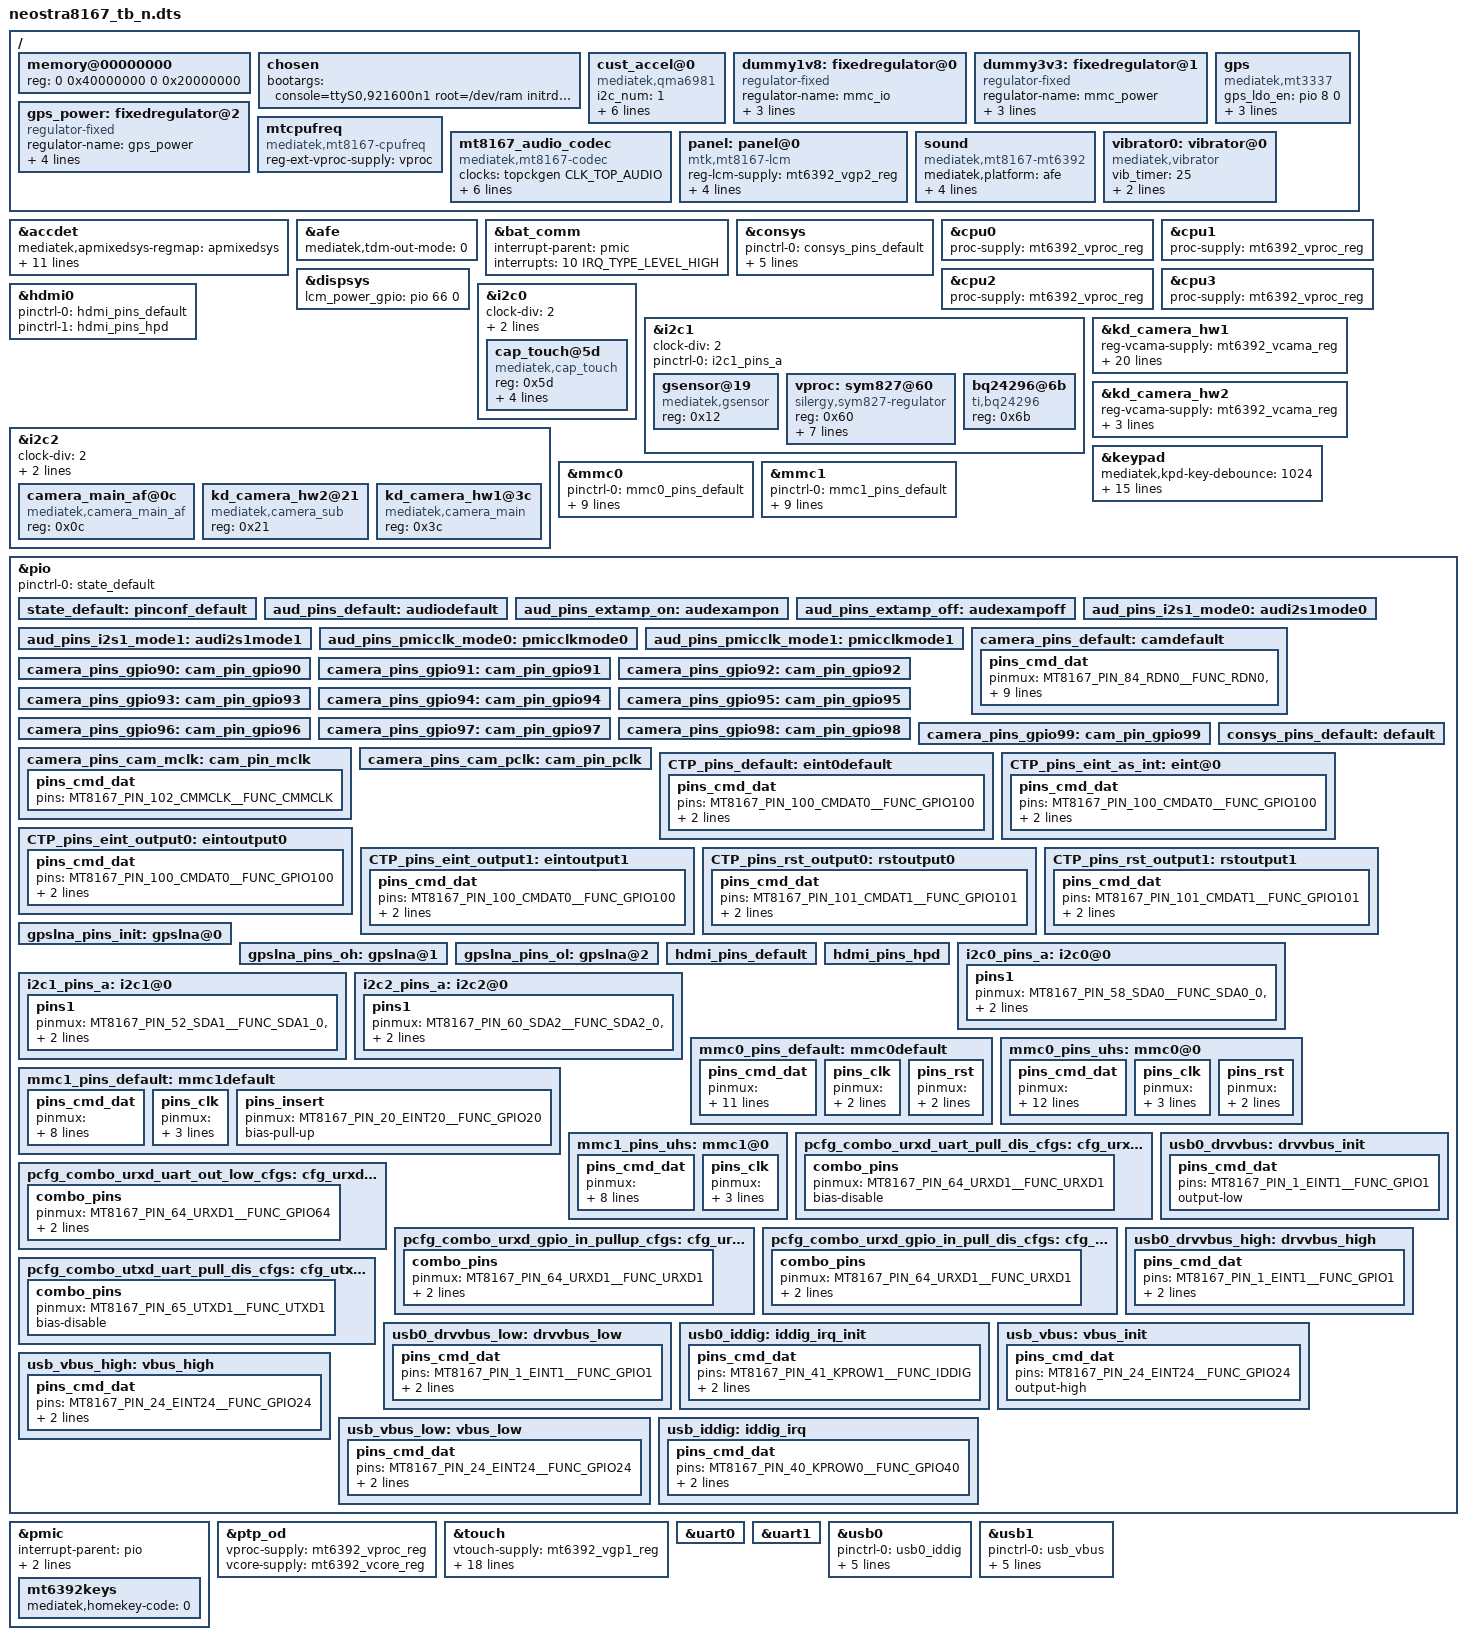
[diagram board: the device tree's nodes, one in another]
/*
 * Copyright (c) 2014-2015 MediaTek Inc.
 *
 * This program is free software; you can redistribute it and/or modify
 * it under the terms of the GNU General Public License version 2 as
 * published by the Free Software Foundation.
 *
 * This program is distributed in the hope that it will be useful,
 * MERCHANTABILITY or FITNESS FOR A PARTICULAR PURPOSE.  See the
 * GNU General Public License for more details.
 */

/dts-v1/;

#include "mt8167.dtsi"
#include "mt6392.dtsi"
#include "neostra8167_tb_n_bat_setting.dtsi"

/ {
	memory@00000000 {
		device_type = "memory";
		reg = <0 0x40000000 0 0x20000000>;
	};

	/* chosen */
	chosen {
		bootargs = "console=ttyS0,921600n1 root=/dev/ram initrd=0x44000200,0x200000";
	};

/* sensor standardization */
	cust_accel@0 {
		compatible = "mediatek,qma6981";
		i2c_num	= <1>;
		i2c_addr = <0x12 0 0 0>;
		direction = <7>;
		power_id = <0xffff>;
		power_vol = <0>;
		firlen = <16>;
		is_batch_supported = <0>;
	};
/* sensor gpio standization */

	dummy1v8: fixedregulator@0 {
		compatible = "regulator-fixed";
		regulator-name = "mmc_io";
		regulator-min-microvolt = <1800000>;
		regulator-max-microvolt = <1800000>;
		regulator-always-on;
	};

	dummy3v3: fixedregulator@1 {
		compatible = "regulator-fixed";
		regulator-name = "mmc_power";
		regulator-min-microvolt = <3300000>;
		regulator-max-microvolt = <3300000>;
		regulator-always-on;
	};
/*Begin Neostra huangxiaohui add:MT3377 GPS gpio*/
/* MT 3337 GPS gpio */
	gps: gps {
		compatible = "mediatek,mt3337";
        gps_ldo_en = <&pio 8 0>;
		gps_rst_en = <&pio 9 0>;
		gps_stb_en = <&pio 15 0>;
		power-supply = <&gps_power>;
		status = "okay";
	};

	gps_power: fixedregulator@2 {
		compatible = "regulator-fixed";
		regulator-name = "gps_power";
		regulator-min-microvolt = <3300000>;
		regulator-max-microvolt = <3300000>;
		gpio = <&pio 8 0>;
		enable-active-high;
	};
/*End Neostra huangxiaohui add:MT3377 GPS gpio*/
	mtcpufreq {
		compatible = "mediatek,mt8167-cpufreq";
		reg-ext-vproc-supply = <&vproc>;
	};

	mt8167_audio_codec: mt8167_audio_codec {
		compatible = "mediatek,mt8167-codec";
		clocks = <&topckgen CLK_TOP_AUDIO>;
		clock-names = "bus";
		mediatek,afe-regmap = <&afe>;
		mediatek,apmixedsys-regmap = <&apmixedsys>;
		mediatek,pwrap-regmap = <&pwrap>;
		mediatek,speaker-mode = <0>; /* 0(CLASSD) 1(CLASSAB) */
		mediatek,dmic-wire-mode = <1>; /* 0(ONE_WIRE) 1(TWO_WIRE) */
		mediatek,headphone-cap-sel = <1>; /* 0(10UF) 1(22UF) 2(33UF) 3(47UF) */
	};

	panel: panel@0 {
		compatible = "mtk,mt8167-lcm";
		reg-lcm-supply = <&mt6392_vgp2_reg>;
		lcm_reset_gpio = <&pio 25 0>;
		lcm_bias_en = <&pio 5 0>;
		lcm_stand_by = <&pio 6 0>;
		lcm_backlight_en = <&pio 54 0>;
		status = "okay";
	};


	sound: sound {
		compatible = "mediatek,mt8167-mt6392";
		mediatek,platform = <&afe>;
		mediatek,hp-spk-amp-warmup-time-us = <40000>;
		pinctrl-names = "default", "extamp_on", "extamp_off";
		pinctrl-0 = <&aud_pins_default>;
		pinctrl-1 = <&aud_pins_extamp_on>;
		pinctrl-2 = <&aud_pins_extamp_off>;
		status = "okay";
	};

	vibrator0:vibrator@0 {
		compatible = "mediatek,vibrator";
		vib_timer = <25>;
		vib_limit = <9>;
		vib_vol= <5>;
	};
};

&accdet {
	mediatek,apmixedsys-regmap = <&apmixedsys>;
	interrupts-extended = <&sysirq GIC_SPI 152 IRQ_TYPE_LEVEL_LOW>,
				<&pio 19 IRQ_TYPE_LEVEL_LOW>;
	interrupts = <19 IRQ_TYPE_LEVEL_LOW>;
	eint-debounce = <256000>;
	accdet-gpio = <&pio 19 0>;
	accdet-mic-vol = <1>;
	headset-mode-setting = <0x500 0x500 1 0x1f0 0x800 0x800 0x20>;
	accdet-plugout-debounce = <20>;
	/*1:ACC mode, 2:low cost without in bias, 6:low cost with in bias*/
	accdet-mic-mode = <1>;
	status = "okay";
};

&afe {
	/* 0(HDMI) 1(I2S) 2(TDM) */
	mediatek,tdm-out-mode = <0>;
};

&bat_comm {
	interrupt-parent = <&pmic>;
	interrupts = <10 IRQ_TYPE_LEVEL_HIGH>;
};

&consys {
	pinctrl-names = "default", "gps_lna_state_init", "gps_lna_state_oh", "gps_lna_state_ol";
	pinctrl-0 = <&consys_pins_default>;
	pinctrl-1 = <&gpslna_pins_init>;
	pinctrl-2 = <&gpslna_pins_oh>;
	pinctrl-3 = <&gpslna_pins_ol>;
	vcn18-supply = <&mt6392_vcn18_reg>;
	vcn35-supply = <&mt6392_vcn35_reg>;
	status = "okay";
};

&cpu0 {
	proc-supply = <&mt6392_vproc_reg>;
};

&cpu1 {
	proc-supply = <&mt6392_vproc_reg>;
};

&cpu2 {
	proc-supply = <&mt6392_vproc_reg>;
};

&cpu3 {
	proc-supply = <&mt6392_vproc_reg>;
};

&dispsys {
	lcm_power_gpio = <&pio 66 0>;
};

&hdmi0 {
	pinctrl-names = "default", "hdmi_hpd";
	pinctrl-0 = <&hdmi_pins_default>;
	pinctrl-1 = <&hdmi_pins_hpd>;
	status = "okay";
};

&i2c0 {
	clock-div = <2>;
	clock-frequency = <400000>;
	pinctrl-names = "default";
	pinctrl-0 = <&i2c0_pins_a>;
	status = "okay";

	cap_touch@5d {
		compatible = "mediatek,cap_touch";
		reg = <0x5d>;
		interrupt-parent = <&pio>;
		interrupts = <100 IRQ_TYPE_EDGE_FALLING>;
		int-gpio = <&pio 100 0>;
		rst-gpio = <&pio 101 0>;
	};
};

&i2c1 {
	clock-div = <2>;
	pinctrl-names = "default";
	pinctrl-0 = <&i2c1_pins_a>;
	status = "okay";

	gsensor@19 {
		compatible = "mediatek,gsensor";
		reg = <0x12>;
	};

	vproc: sym827@60 {
		compatible = "silergy,sym827-regulator";
		reg = <0x60>;
		regulator-name = "vproc";
		regulator-min-microvolt = <600000>;
		regulator-max-microvolt = <1387500>;
		regulator-enable-ramp-delay = <400>;
		regulator-ramp-delay = <8333>;
		regulator-always-on;
		vsel-gpio = <&pio 34 0>;
	};

	bq24296@6b {
		compatible = "ti,bq24296";
		reg = <0x6b>;
	};
};

&i2c2 {
	clock-div = <2>;
	clock-frequency = <400000>;
	pinctrl-names = "default";
	pinctrl-0 = <&i2c2_pins_a>;
	status = "okay";

	camera_main_af@0c {
		compatible = "mediatek,camera_main_af";
		reg = <0x0c>;
	};

	kd_camera_hw2@21 {
		compatible = "mediatek,camera_sub";
		reg = <0x21>;
	};

	kd_camera_hw1@3c {
		compatible = "mediatek,camera_main";
		reg = <0x3c>;
	};
};

/* Main Cam */
&kd_camera_hw1 {
	reg-vcama-supply = <&mt6392_vcama_reg>;		/* AVDD */
	reg-vcamd-supply = <&mt6392_vcamd_reg>;		/* DVDD */
	reg-vcamio-supply = <&mt6392_vcamio_reg>;	/* DOVDD */
	reg-vcamaf-supply = <&mt6392_vcamaf_reg>;	/* AFVDD */

	pinctrl-names = "default",
		"cam_mclk", "cam_pclk",
		"cam_gpio90",  "cam_gpio91", "cam_gpio92", "cam_gpio93",  "cam_gpio94",
		"cam_gpio95",  "cam_gpio96", "cam_gpio97", "cam_gpio98",  "cam_gpio99";

	pinctrl-0 = <&camera_pins_default>;
	pinctrl-1 = <&camera_pins_cam_mclk>;
	pinctrl-2 = <&camera_pins_cam_pclk>;
	pinctrl-3 = <&camera_pins_gpio90>;
	pinctrl-4 = <&camera_pins_gpio91>;
	pinctrl-5 = <&camera_pins_gpio92>;
	pinctrl-6 = <&camera_pins_gpio93>;
	pinctrl-7 = <&camera_pins_gpio94>;
	pinctrl-8 = <&camera_pins_gpio95>;
	pinctrl-9 = <&camera_pins_gpio96>;
	pinctrl-10 = <&camera_pins_gpio97>;
	pinctrl-11 = <&camera_pins_gpio98>;
	pinctrl-12 = <&camera_pins_gpio99>;

	cam0_rst = <&pio 49 0>;
	cam0_pdn = <&pio 48 0>;
	cam1_rst = <&pio 50 0>;
	cam1_pdn = <&pio 51 0>;
	status = "okay";
};

/* Sub Cam */
/* Same power pins as Main, actually, it can be commented */
&kd_camera_hw2{
	reg-vcama-supply = <&mt6392_vcama_reg>;		/* AVDD */
	reg-vcamd-supply = <&mt6392_vcamd_reg>;		/* DVDD */
	reg-vcamio-supply = <&mt6392_vcamio_reg>;	/* DOVDD */
	reg-vcamaf-supply = <&mt6392_vcamaf_reg>;	/* AFVDD */
};

&keypad {
	mediatek,kpd-key-debounce = <1024>;
	mediatek,kpd-sw-pwrkey = <116>;
	mediatek,kpd-hw-pwrkey = <8>;
	mediatek,kpd-sw-rstkey  = <0>;
	mediatek,kpd-hw-rstkey = <17>;
	mediatek,kpd-use-extend-type = <0>;
	/*HW Keycode [0~71] -> Linux Keycode*/
	mediatek,kpd-hw-map-num = <72>;
	mediatek,kpd-hw-init-map = <114 115 0 0 0 0 0 0 0 0 0 0 0 0 0 0 0 0 0 0 0 0 0 0
			0 0 0 0 0 0 0 0 0 0 0 0 0 0 0 0 0 0 0 0 0 0 0 0
			0 0 0 0 0 0 0 0 0 0 0 0 0 0 0 0 0 0 0 0 0 0 0 0 >;
	mediatek,kpd-pwrkey-eint-gpio = <0>;
	mediatek,kpd-pwkey-gpio-din  = <0>;
	mediatek,kpd-hw-dl-key0 = <0>;
	mediatek,kpd-hw-dl-key1 = <17>;
	mediatek,kpd-hw-dl-key2 = <8>;
	mediatek,kpd-hw-recovery-key = <17>;
	mediatek,kpd-hw-factory-key  = <0>;
};

&mmc0 {
	pinctrl-names = "default", "state_uhs";
	pinctrl-0 = <&mmc0_pins_default>;
	pinctrl-1 = <&mmc0_pins_uhs>;
	status = "okay";
	bus-width = <8>;
	max-frequency = <200000000>;
	cap-mmc-highspeed;
	mmc-hs200-1_8v;
	cap-mmc-hw-reset;
	vmmc-supply = <&mt6392_vemc3v3_reg>;
	vqmmc-supply = <&mt6392_vio18_reg>;
	non-removable;
};

&mmc1 {
	pinctrl-names = "default", "state_uhs";
	pinctrl-0 = <&mmc1_pins_default>;
	pinctrl-1 = <&mmc1_pins_uhs>;
	status = "okay";
	bus-width = <4>;
	max-frequency = <200000000>;
	cap-sd-highspeed;
	sd-uhs-sdr50;
	sd-uhs-sdr104;
	cd-gpios = <&pio 20 0>;
	vmmc-supply = <&mt6392_vmch_reg>;
	vqmmc-supply = <&mt6392_vmc_reg>;
};


&pio {
	pinctrl-names = "default";
	pinctrl-0 = <&state_default>;

	state_default:pinconf_default {
	};

	aud_pins_default: audiodefault {
	};

	aud_pins_extamp_on: audexampon {
	};

	aud_pins_extamp_off: audexampoff {
	};

	aud_pins_i2s1_mode0: audi2s1mode0 {
	};

	aud_pins_i2s1_mode1: audi2s1mode1 {
	};

	aud_pins_pmicclk_mode0: pmicclkmode0 {
	};

	aud_pins_pmicclk_mode1: pmicclkmode1 {
	};

	/* CAMERA GPIO standardization */
	/* default mode */
	camera_pins_default: camdefault {

		pins_cmd_dat {
			pinmux = <MT8167_PIN_84_RDN0__FUNC_RDN0>,
				<MT8167_PIN_85_RDP0__FUNC_RDP0>,
				<MT8167_PIN_86_RDN1__FUNC_RDN1>,
				<MT8167_PIN_87_RDP1__FUNC_RDP1>,
				<MT8167_PIN_88_RCN__FUNC_RCN>,
				<MT8167_PIN_89_RCP__FUNC_RCP>,
				<MT8167_PIN_90_RDN2__FUNC_RDN2>,
				<MT8167_PIN_91_RDP2__FUNC_RDP2>,
				<MT8167_PIN_92_RDN3__FUNC_RDN3>,
				<MT8167_PIN_93_RDP3__FUNC_RDP3>;
		};
	};



	camera_pins_gpio90: cam_pin_gpio90 {
	};

	camera_pins_gpio91: cam_pin_gpio91 {
	};

	camera_pins_gpio92: cam_pin_gpio92 {
	};

	camera_pins_gpio93: cam_pin_gpio93 {
	};

	camera_pins_gpio94: cam_pin_gpio94 {
	};

	camera_pins_gpio95: cam_pin_gpio95 {
	};

	camera_pins_gpio96: cam_pin_gpio96 {
	};

	camera_pins_gpio97: cam_pin_gpio97 {
	};

	camera_pins_gpio98: cam_pin_gpio98 {
	};

	camera_pins_gpio99: cam_pin_gpio99 {
	};
	camera_pins_cam_mclk: cam_pin_mclk {
		pins_cmd_dat {
			pins = <MT8167_PIN_102_CMMCLK__FUNC_CMMCLK>;
		};
	};
	camera_pins_cam_pclk: cam_pin_pclk {
	};

	/* CONSYS GPIO Settings - Start */
	consys_pins_default: default {

	};
	/* CONSYS GPIO Settings - End */

	CTP_pins_default: eint0default {
		pins_cmd_dat {
			pins = <MT8167_PIN_100_CMDAT0__FUNC_GPIO100>;
			slew-rate = <0>;
			bias-disable;
		};
	};

	CTP_pins_eint_as_int: eint@0 {
		pins_cmd_dat {
			pins = <MT8167_PIN_100_CMDAT0__FUNC_GPIO100>;
			slew-rate = <0>;
			bias-disable;
		};
	};

	CTP_pins_eint_output0: eintoutput0 {
		pins_cmd_dat {
			pins = <MT8167_PIN_100_CMDAT0__FUNC_GPIO100>;
			slew-rate = <1>;
			output-low;
		};
	};

	CTP_pins_eint_output1: eintoutput1 {
		pins_cmd_dat {
			pins = <MT8167_PIN_100_CMDAT0__FUNC_GPIO100>;
			slew-rate = <1>;
			output-high;
		};
	};

	CTP_pins_rst_output0: rstoutput0 {
		pins_cmd_dat {
			pins = <MT8167_PIN_101_CMDAT1__FUNC_GPIO101>;
			slew-rate = <1>;
			output-low;
		};
	};

	CTP_pins_rst_output1: rstoutput1 {
		pins_cmd_dat {
			pins = <MT8167_PIN_101_CMDAT1__FUNC_GPIO101>;
			slew-rate = <1>;
			output-high;
		};
	};

	/* CONSYS GPIO Settings - Start */
	consys_pins_default:default{
	};
	
	gpslna_pins_init: gpslna@0 {
	};

	gpslna_pins_oh: gpslna@1 {
	};

	gpslna_pins_ol: gpslna@2 {
	};
	/* CONSYS GPIO Settings - End */

	hdmi_pins_default: hdmi_pins_default {
	};

	hdmi_pins_hpd: hdmi_pins_hpd {
	};

	i2c0_pins_a: i2c0@0 {
		pins1 {
			pinmux = <MT8167_PIN_58_SDA0__FUNC_SDA0_0>,
				 <MT8167_PIN_59_SCL0__FUNC_SCL0_0>;
			bias-disable;
		};
	};

	i2c1_pins_a: i2c1@0 {
		pins1 {
			pinmux = <MT8167_PIN_52_SDA1__FUNC_SDA1_0>,
				 <MT8167_PIN_53_SCL1__FUNC_SCL1_0>;
			bias-disable;
		};
	};

	i2c2_pins_a: i2c2@0 {
		pins1 {
			pinmux = <MT8167_PIN_60_SDA2__FUNC_SDA2_0>,
				 <MT8167_PIN_61_SCL2__FUNC_SCL2_0>;
			bias-disable;
		};
	};


	mmc0_pins_default: mmc0default {
		pins_cmd_dat {
			pinmux = <MT8167_PIN_120_MSDC0_DAT0__FUNC_MSDC0_DAT0>,
				<MT8167_PIN_119_MSDC0_DAT1__FUNC_MSDC0_DAT1>,
				<MT8167_PIN_118_MSDC0_DAT2__FUNC_MSDC0_DAT2>,
				<MT8167_PIN_117_MSDC0_DAT3__FUNC_MSDC0_DAT3>,
				<MT8167_PIN_113_MSDC0_DAT4__FUNC_MSDC0_DAT4>,
				<MT8167_PIN_112_MSDC0_DAT5__FUNC_MSDC0_DAT5>,
				<MT8167_PIN_111_MSDC0_DAT6__FUNC_MSDC0_DAT6>,
				<MT8167_PIN_110_MSDC0_DAT7__FUNC_MSDC0_DAT7>,
				<MT8167_PIN_115_MSDC0_CMD__FUNC_MSDC0_CMD>;
			input-enable;
			bias-pull-up;
		};

		pins_clk {
			pinmux = <MT8167_PIN_116_MSDC0_CLK__FUNC_MSDC0_CLK>;
			bias-pull-down;
		};

		pins_rst {
			pinmux = <MT8167_PIN_114_MSDC0_RSTB__FUNC_MSDC0_RSTB>;
			bias-pull-up;
		};
	};

	mmc0_pins_uhs: mmc0@0{
		pins_cmd_dat {
			pinmux = <MT8167_PIN_120_MSDC0_DAT0__FUNC_MSDC0_DAT0>,
				<MT8167_PIN_119_MSDC0_DAT1__FUNC_MSDC0_DAT1>,
				<MT8167_PIN_118_MSDC0_DAT2__FUNC_MSDC0_DAT2>,
				<MT8167_PIN_117_MSDC0_DAT3__FUNC_MSDC0_DAT3>,
				<MT8167_PIN_113_MSDC0_DAT4__FUNC_MSDC0_DAT4>,
				<MT8167_PIN_112_MSDC0_DAT5__FUNC_MSDC0_DAT5>,
				<MT8167_PIN_111_MSDC0_DAT6__FUNC_MSDC0_DAT6>,
				<MT8167_PIN_110_MSDC0_DAT7__FUNC_MSDC0_DAT7>,
				<MT8167_PIN_115_MSDC0_CMD__FUNC_MSDC0_CMD>;
			input-enable;
			drive-strength = <MTK_DRIVE_6mA>;
			bias-pull-up = <MTK_PUPD_SET_R1R0_01>;
		};

		pins_clk {
			pinmux = <MT8167_PIN_116_MSDC0_CLK__FUNC_MSDC0_CLK>;
			drive-strength = <MTK_DRIVE_8mA>;
			bias-pull-down = <MTK_PUPD_SET_R1R0_10>;
		};

		pins_rst {
			pinmux = <MT8167_PIN_114_MSDC0_RSTB__FUNC_MSDC0_RSTB>;
			bias-pull-up;
		};
	};

	mmc1_pins_default: mmc1default {
		pins_cmd_dat {
			pinmux = <MT8167_PIN_106_MSDC1_DAT0__FUNC_MSDC1_DAT0>,
				<MT8167_PIN_107_MSDC1_DAT1__FUNC_MSDC1_DAT1>,
				<MT8167_PIN_108_MSDC1_DAT2__FUNC_MSDC1_DAT2>,
				<MT8167_PIN_109_MSDC1_DAT3__FUNC_MSDC1_DAT3>,
				<MT8167_PIN_104_MSDC1_CMD__FUNC_MSDC1_CMD>;
			input-enable;
			drive-strength = <MTK_DRIVE_6mA>;
			bias-pull-up = <MTK_PUPD_SET_R1R0_01>;
		};

		pins_clk {
			pinmux = <MT8167_PIN_105_MSDC1_CLK__FUNC_MSDC1_CLK>;
			drive-strength = <MTK_DRIVE_6mA>;
			bias-pull-down = <MTK_PUPD_SET_R1R0_10>;
		};

		pins_insert {
			pinmux = <MT8167_PIN_20_EINT20__FUNC_GPIO20>;
			bias-pull-up;
		};
	};

	mmc1_pins_uhs: mmc1@0 {
		pins_cmd_dat {
			pinmux = <MT8167_PIN_106_MSDC1_DAT0__FUNC_MSDC1_DAT0>,
				<MT8167_PIN_107_MSDC1_DAT1__FUNC_MSDC1_DAT1>,
				<MT8167_PIN_108_MSDC1_DAT2__FUNC_MSDC1_DAT2>,
				<MT8167_PIN_109_MSDC1_DAT3__FUNC_MSDC1_DAT3>,
				<MT8167_PIN_104_MSDC1_CMD__FUNC_MSDC1_CMD>;
			input-enable;
			drive-strength = <MTK_DRIVE_6mA>;
			bias-pull-up = <MTK_PUPD_SET_R1R0_01>;
		};

		pins_clk {
			pinmux = <MT8167_PIN_105_MSDC1_CLK__FUNC_MSDC1_CLK>;
			drive-strength = <MTK_DRIVE_8mA>;
			bias-pull-down = <MTK_PUPD_SET_R1R0_10>;
		};
	};



    /* Connectivity GPIO start */


	pcfg_combo_urxd_uart_pull_dis_cfgs:cfg_urxd_pull_dis {
		combo_pins {
			pinmux = <MT8167_PIN_64_URXD1__FUNC_URXD1>;
			bias-disable;
		};
	};

	pcfg_combo_urxd_uart_out_low_cfgs:cfg_urxd_out_low {
		combo_pins {
			pinmux = <MT8167_PIN_64_URXD1__FUNC_GPIO64>;
			slew-rate = <1>;
			output-low;
		};
	};

	pcfg_combo_urxd_gpio_in_pullup_cfgs:cfg_urxd_in_pullup {
		combo_pins {
			pinmux = <MT8167_PIN_64_URXD1__FUNC_URXD1>;
			input-enable;
			bias-pull-up;
		};
	};

	pcfg_combo_urxd_gpio_in_pull_dis_cfgs:cfg_urxd_in_pull_dis {
		combo_pins {
			pinmux = <MT8167_PIN_64_URXD1__FUNC_URXD1>;
			input-enable;
			bias-disable;
		};
	};

	pcfg_combo_utxd_uart_pull_dis_cfgs:cfg_utxd_pull_dis {
		combo_pins {
			pinmux = <MT8167_PIN_65_UTXD1__FUNC_UTXD1>;
			bias-disable;
		};
	};
/* Connectivity GPIO end */

/* USB GPIO start */
	usb0_drvvbus: drvvbus_init {
		pins_cmd_dat {
			pins = <MT8167_PIN_1_EINT1__FUNC_GPIO1>;
			output-low;
		};
	};

	usb0_drvvbus_high: drvvbus_high {
		pins_cmd_dat {
			pins = <MT8167_PIN_1_EINT1__FUNC_GPIO1>;
			slew-rate = <1>;
			output-high;
		};
	};

	usb0_drvvbus_low: drvvbus_low {
		pins_cmd_dat {
			pins = <MT8167_PIN_1_EINT1__FUNC_GPIO1>;
			slew-rate = <1>;
			output-low;
		};
	};

	usb0_iddig: iddig_irq_init {
		pins_cmd_dat {
			pins = <MT8167_PIN_41_KPROW1__FUNC_IDDIG>;
			slew-rate = <0>;
			bias-pull-up = <00>;
		};
	};

	usb_vbus: vbus_init {
		pins_cmd_dat {
			pins = <MT8167_PIN_24_EINT24__FUNC_GPIO24>;
			output-high;
		};
	};

	usb_vbus_high: vbus_high {
		pins_cmd_dat {
			pins = <MT8167_PIN_24_EINT24__FUNC_GPIO24>;
			slew-rate = <1>;
			output-high;
		};
	};

	usb_vbus_low: vbus_low {
		pins_cmd_dat {
			pins = <MT8167_PIN_24_EINT24__FUNC_GPIO24>;
			slew-rate = <1>;
			output-low;
		};
	};

	usb_iddig: iddig_irq {
		pins_cmd_dat {
			pins = <MT8167_PIN_40_KPROW0__FUNC_GPIO40>;
			slew-rate = <0>;
			bias-pull-up = <00>;
		};
	};
/* USB GPIO end */
};

&pmic {
	interrupt-parent = <&pio>;
	interrupts = <28 IRQ_TYPE_LEVEL_HIGH>;
	interrupt-controller;
	#interrupt-cells = <2>;

	mt6392keys: mt6392keys {
		mediatek,homekey-code = <0>;
	};
};

&ptp_od {
	vproc-supply = <&mt6392_vproc_reg>;
	vcore-supply = <&mt6392_vcore_reg>;
};

&touch {
	vtouch-supply = <&mt6392_vgp1_reg>;
	tpd-resolution = <600 1024>;
	use-tpd-button = <0>;
	tpd-key-num = <3>;
	tpd-key-local= <139 172 158 0>;
	tpd-key-dim-local = <90 883 100 40 230 883 100 40 370 883 100 40 0 0 0 0>;
	tpd-max-touch-num = <5>;
	tpd-filter-enable = <1>;
	tpd-filter-pixel-density = <124>;
	tpd-filter-custom-prameters = <0 0 0 0 0 0 0 0 0 0 0 0>;
	tpd-filter-custom-speed = <0 0 0>;
	pinctrl-names = "default", "state_eint_as_int", "state_eint_output0", "state_eint_output1",
		"state_rst_output0", "state_rst_output1";
	pinctrl-0 = <&CTP_pins_default>;
	pinctrl-1 = <&CTP_pins_eint_as_int>;
	pinctrl-2 = <&CTP_pins_eint_output0>;
	pinctrl-3 = <&CTP_pins_eint_output1>;
	pinctrl-4 = <&CTP_pins_rst_output0>;
	pinctrl-5 = <&CTP_pins_rst_output1>;
	status = "okay";
};

&uart0 {
	status="okay";
};

&uart1 {
	status="okay";
};

&usb0 {
	pinctrl-names = "iddig_irq_init", "drvvbus_init", "drvvbus_low", "drvvbus_high";
	pinctrl-0 = <&usb0_iddig>;
	pinctrl-1 = <&usb0_drvvbus>;
	pinctrl-2 = <&usb0_drvvbus_low>;
	pinctrl-3 = <&usb0_drvvbus_high>;
	usb-power-supply = <&mt6392_vusb_reg>;
	status = "okay";
	drvvbus_gpio = <&pio 1 0>;
};

&usb1 {
	pinctrl-names = "vbus_init", "vbus_low", "vbus_high", "iddig_irq";
	pinctrl-0 = <&usb_vbus>;
	pinctrl-1 = <&usb_vbus_low>;
	pinctrl-2 = <&usb_vbus_high>;
	pinctrl-3 = <&usb_iddig>;
	status = "okay";
	vubs_gpio = <&pio 24 0>;
	iddig_gpio = <&pio 40 0>;
};
